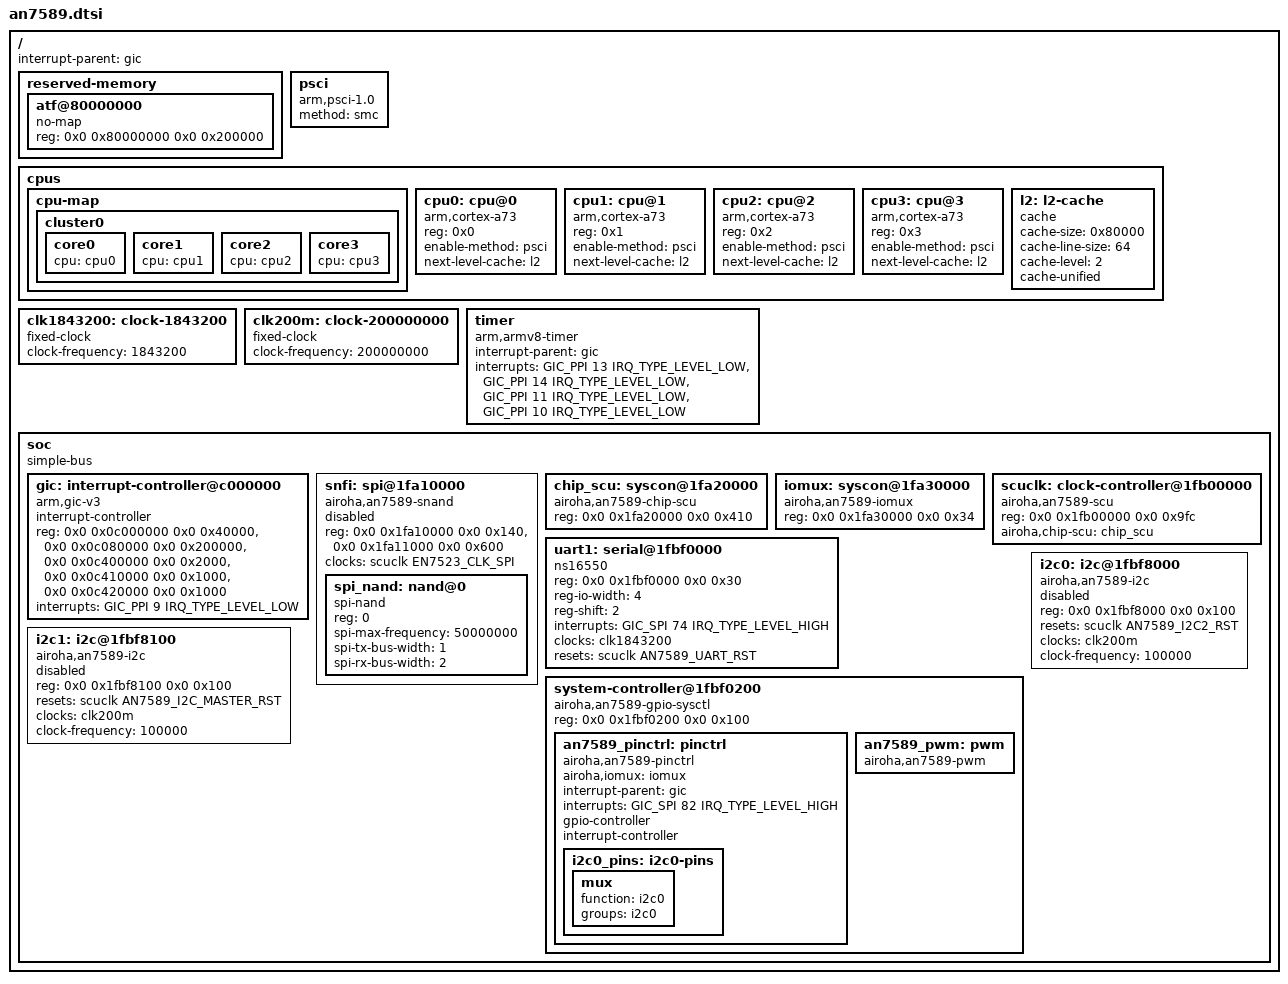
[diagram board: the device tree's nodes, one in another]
// SPDX-License-Identifier: (GPL-2.0-only OR BSD-2-Clause)

#include <dt-bindings/interrupt-controller/irq.h>
#include <dt-bindings/interrupt-controller/arm-gic.h>
#include <dt-bindings/clock/en7523-clk.h>
#include <dt-bindings/reset/airoha,an7589-reset.h>

/ {
	interrupt-parent = <&gic>;
	#address-cells = <2>;
	#size-cells = <2>;

	reserved-memory {
		#address-cells = <2>;
		#size-cells = <2>;
		ranges;

		atf@80000000 {
			no-map;
			reg = <0x0 0x80000000 0x0 0x200000>;
		};
	};

	psci {
		compatible = "arm,psci-1.0";
		method = "smc";
	};

	cpus {
		#address-cells = <1>;
		#size-cells = <0>;

		cpu-map {
			cluster0 {
				core0 {
					cpu = <&cpu0>;
				};

				core1 {
					cpu = <&cpu1>;
				};

				core2 {
					cpu = <&cpu2>;
				};

				core3 {
					cpu = <&cpu3>;
				};
			};
		};

		cpu0: cpu@0 {
			device_type = "cpu";
			compatible = "arm,cortex-a73";
			reg = <0x0>;
			enable-method = "psci";
			next-level-cache = <&l2>;
		};

		cpu1: cpu@1 {
			device_type = "cpu";
			compatible = "arm,cortex-a73";
			reg = <0x1>;
			enable-method = "psci";
			next-level-cache = <&l2>;
		};

		cpu2: cpu@2 {
			device_type = "cpu";
			compatible = "arm,cortex-a73";
			reg = <0x2>;
			enable-method = "psci";
			next-level-cache = <&l2>;
		};

		cpu3: cpu@3 {
			device_type = "cpu";
			compatible = "arm,cortex-a73";
			reg = <0x3>;
			enable-method = "psci";
			next-level-cache = <&l2>;
		};

		l2: l2-cache {
			compatible = "cache";
			cache-size = <0x80000>;
			cache-line-size = <64>;
			cache-level = <2>;
			cache-unified;
		};
	};

	clk1843200: clock-1843200 {
		compatible = "fixed-clock";
		#clock-cells = <0>;
		clock-frequency = <1843200>;
	};

	clk200m: clock-200000000 {
		compatible = "fixed-clock";
		#clock-cells = <0>;
		clock-frequency = <200000000>;
	};

	timer {
		compatible = "arm,armv8-timer";
		interrupt-parent = <&gic>;
		interrupts = <GIC_PPI 13 IRQ_TYPE_LEVEL_LOW>,
			     <GIC_PPI 14 IRQ_TYPE_LEVEL_LOW>,
			     <GIC_PPI 11 IRQ_TYPE_LEVEL_LOW>,
			     <GIC_PPI 10 IRQ_TYPE_LEVEL_LOW>;
	};

	soc {
		compatible = "simple-bus";
		#address-cells = <2>;
		#size-cells = <2>;
		ranges;

		gic: interrupt-controller@c000000 {
			compatible = "arm,gic-v3";
			interrupt-controller;
			#interrupt-cells = <3>;
			reg = <0x0 0x0c000000 0x0 0x40000>,
			      <0x0 0x0c080000 0x0 0x200000>,
			      <0x0 0x0c400000 0x0 0x2000>,
			      <0x0 0x0c410000 0x0 0x1000>,
			      <0x0 0x0c420000 0x0 0x1000>;
			interrupts = <GIC_PPI 9 IRQ_TYPE_LEVEL_LOW>;
		};

		snfi: spi@1fa10000 {
			compatible = "airoha,an7589-snand", "airoha,en7581-snand";
			reg = <0x0 0x1fa10000 0x0 0x140>,
			      <0x0 0x1fa11000 0x0 0x600>;

			clocks = <&scuclk EN7523_CLK_SPI>;
			clock-names = "spi";

			#address-cells = <1>;
			#size-cells = <0>;

			status = "disabled";

			spi_nand: nand@0 {
				compatible = "spi-nand";
				reg = <0>;

				spi-max-frequency = <50000000>;
				spi-tx-bus-width = <1>;
				spi-rx-bus-width = <2>;
			};
		};

		chip_scu: syscon@1fa20000 {
			compatible = "airoha,an7589-chip-scu", "syscon";
			reg = <0x0 0x1fa20000 0x0 0x410>;
		};

		iomux: syscon@1fa30000 {
			compatible = "airoha,an7589-iomux", "syscon";
			reg = <0x0 0x1fa30000 0x0 0x34>;
		};

		scuclk: clock-controller@1fb00000 {
			compatible = "airoha,an7589-scu";
			reg = <0x0 0x1fb00000 0x0 0x9fc>;
			airoha,chip-scu = <&chip_scu>;
			#clock-cells = <1>;
			#reset-cells = <1>;
		};

		uart1: serial@1fbf0000 {
			compatible = "ns16550";
			reg = <0x0 0x1fbf0000 0x0 0x30>;
			reg-io-width = <4>;
			reg-shift = <2>;
			interrupts = <GIC_SPI 74 IRQ_TYPE_LEVEL_HIGH>;
			clocks = <&clk1843200>;
			resets = <&scuclk AN7589_UART_RST>;
		};

		system-controller@1fbf0200 {
			compatible = "airoha,an7589-gpio-sysctl", "syscon",
				     "simple-mfd";
			reg = <0x0 0x1fbf0200 0x0 0x100>;

			an7589_pinctrl: pinctrl {
				compatible = "airoha,an7589-pinctrl";
				airoha,iomux = <&iomux>;

				interrupt-parent = <&gic>;
				interrupts = <GIC_SPI 82 IRQ_TYPE_LEVEL_HIGH>;

				gpio-controller;
				#gpio-cells = <2>;

				interrupt-controller;
				#interrupt-cells = <2>;

				i2c0_pins: i2c0-pins {
					mux {
						function = "i2c0";
						groups = "i2c0";
					};
				};
			};

			an7589_pwm: pwm {
				compatible = "airoha,an7589-pwm";

				#pwm-cells = <3>;
			};
		};

		i2c0: i2c@1fbf8000 {
			compatible = "airoha,an7589-i2c";
			reg = <0x0 0x1fbf8000 0x0 0x100>;

			resets = <&scuclk AN7589_I2C2_RST>;

			clocks = <&clk200m>;
			clock-frequency = <100000>;

			#address-cells = <1>;
			#size-cells = <0>;

			status = "disabled";
		};

		i2c1: i2c@1fbf8100 {
			compatible = "airoha,an7589-i2c";
			reg = <0x0 0x1fbf8100 0x0 0x100>;

			resets = <&scuclk AN7589_I2C_MASTER_RST>;

			clocks = <&clk200m>;
			clock-frequency = <100000>;

			#address-cells = <1>;
			#size-cells = <0>;

			status = "disabled";
		};
	};
};
